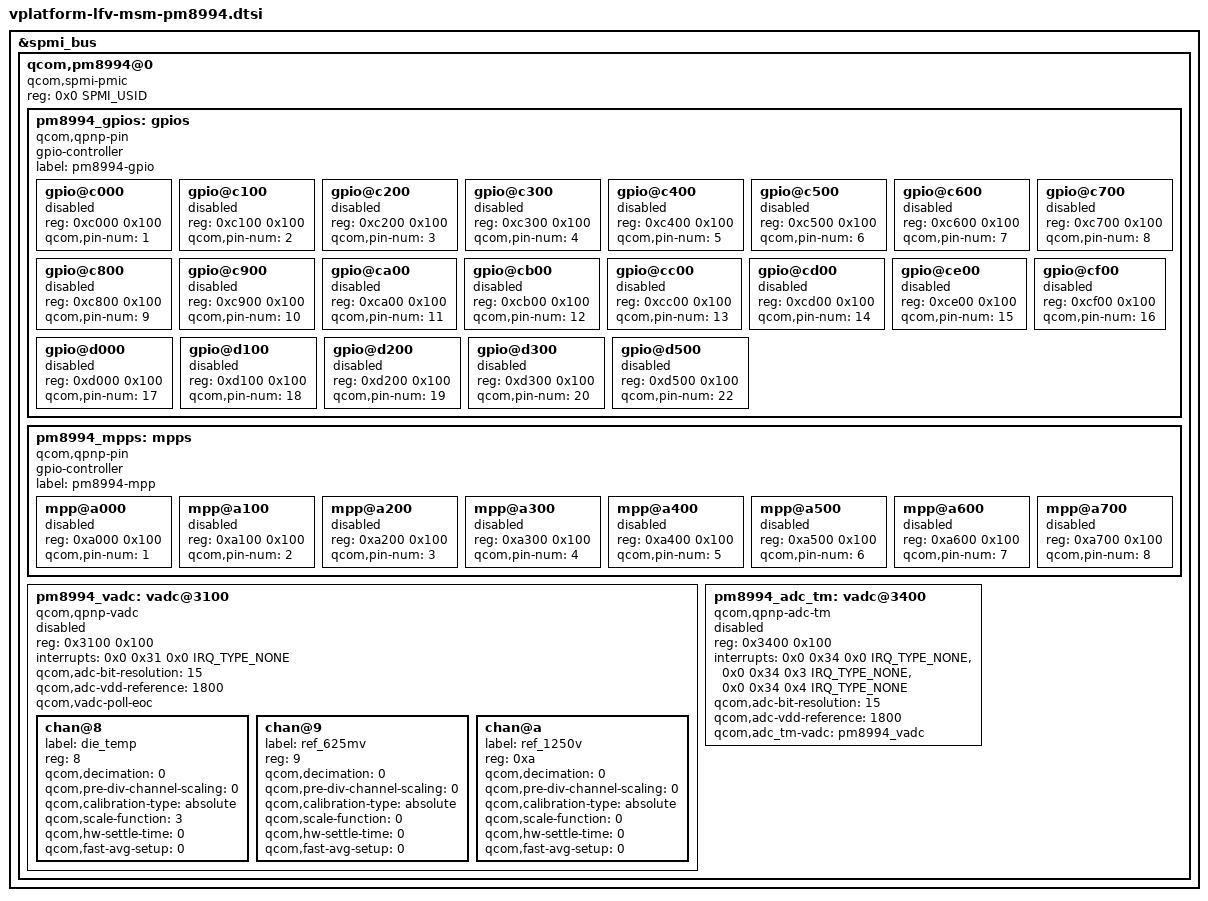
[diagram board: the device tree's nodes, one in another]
/* Copyright (c) 2018, The Linux Foundation. All rights reserved.
 *
 * This program is free software; you can redistribute it and/or modify
 * it under the terms of the GNU General Public License version 2 and
 * only version 2 as published by the Free Software Foundation.
 *
 * This program is distributed in the hope that it will be useful,
 * but WITHOUT ANY WARRANTY; without even the implied warranty of
 * MERCHANTABILITY or FITNESS FOR A PARTICULAR PURPOSE.  See the
 * GNU General Public License for more details.
 */

#include <dt-bindings/spmi/spmi.h>
#include <dt-bindings/interrupt-controller/irq.h>

&spmi_bus {
	qcom,pm8994@0 {
		compatible ="qcom,spmi-pmic";
		reg = <0x0 SPMI_USID>;
		#address-cells = <2>;
		#size-cells = <0>;

		pm8994_gpios: gpios {
			compatible = "qcom,qpnp-pin";
			gpio-controller;
			#gpio-cells = <2>;
			#address-cells = <1>;
			#size-cells = <1>;
			label = "pm8994-gpio";

			gpio@c000 {
				reg = <0xc000 0x100>;
				qcom,pin-num = <1>;
				status = "disabled";
			};

			gpio@c100 {
				reg = <0xc100 0x100>;
				qcom,pin-num = <2>;
				status = "disabled";
			};

			gpio@c200 {
				reg = <0xc200 0x100>;
				qcom,pin-num = <3>;
				status = "disabled";
			};

			gpio@c300 {
				reg = <0xc300 0x100>;
				qcom,pin-num = <4>;
				status = "disabled";
			};

			gpio@c400 {
				reg = <0xc400 0x100>;
				qcom,pin-num = <5>;
				status = "disabled";
			};

			gpio@c500 {
				reg = <0xc500 0x100>;
				qcom,pin-num = <6>;
				status = "disabled";
			};

			gpio@c600 {
				reg = <0xc600 0x100>;
				qcom,pin-num = <7>;
				status = "disabled";
			};

			gpio@c700 {
				reg = <0xc700 0x100>;
				qcom,pin-num = <8>;
				status = "disabled";
			};

			gpio@c800 {
				reg = <0xc800 0x100>;
				qcom,pin-num = <9>;
				status = "disabled";
			};

			gpio@c900 {
				reg = <0xc900 0x100>;
				qcom,pin-num = <10>;
				status = "disabled";
			};

			gpio@ca00 {
				reg = <0xca00 0x100>;
				qcom,pin-num = <11>;
				status = "disabled";
			};

			gpio@cb00 {
				reg = <0xcb00 0x100>;
				qcom,pin-num = <12>;
				status = "disabled";
			};

			gpio@cc00 {
				reg = <0xcc00 0x100>;
				qcom,pin-num = <13>;
				status = "disabled";
			};

			gpio@cd00 {
				reg = <0xcd00 0x100>;
				qcom,pin-num = <14>;
				status = "disabled";
			};

			gpio@ce00 {
				reg = <0xce00 0x100>;
				qcom,pin-num = <15>;
				status = "disabled";
			};

			gpio@cf00 {
				reg = <0xcf00 0x100>;
				qcom,pin-num = <16>;
				status = "disabled";
			};

			gpio@d000 {
				reg = <0xd000 0x100>;
				qcom,pin-num = <17>;
				status = "disabled";
			};

			gpio@d100 {
				reg = <0xd100 0x100>;
				qcom,pin-num = <18>;
				status = "disabled";
			};

			gpio@d200 {
				reg = <0xd200 0x100>;
				qcom,pin-num = <19>;
				status = "disabled";
			};

			gpio@d300 {
				reg = <0xd300 0x100>;
				qcom,pin-num = <20>;
				status = "disabled";
			};

			gpio@d500 {
				reg = <0xd500 0x100>;
				qcom,pin-num = <22>;
				status = "disabled";
			};
		};

		pm8994_mpps: mpps {
			compatible = "qcom,qpnp-pin";
			gpio-controller;
			#gpio-cells = <2>;
			#address-cells = <1>;
			#size-cells = <1>;
			label = "pm8994-mpp";

			mpp@a000 {
				reg = <0xa000 0x100>;
				qcom,pin-num = <1>;
				status = "disabled";
			};

			mpp@a100 {
				reg = <0xa100 0x100>;
				qcom,pin-num = <2>;
				status = "disabled";
			};

			mpp@a200 {
				reg = <0xa200 0x100>;
				qcom,pin-num = <3>;
				status = "disabled";
			};

			mpp@a300 {
				reg = <0xa300 0x100>;
				qcom,pin-num = <4>;
				status = "disabled";
			};

			mpp@a400 {
				reg = <0xa400 0x100>;
				qcom,pin-num = <5>;
				status = "disabled";
			};

			mpp@a500 {
				reg = <0xa500 0x100>;
				qcom,pin-num = <6>;
				status = "disabled";
			};

			mpp@a600 {
				reg = <0xa600 0x100>;
				qcom,pin-num = <7>;
				status = "disabled";
			};

			mpp@a700 {
				reg = <0xa700 0x100>;
				qcom,pin-num = <8>;
				status = "disabled";
			};
		};

		pm8994_vadc: vadc@3100 {
			compatible = "qcom,qpnp-vadc";
			reg = <0x3100 0x100>;
			#address-cells = <1>;
			#size-cells = <0>;
			interrupts = <0x0 0x31 0x0 IRQ_TYPE_NONE>;
			interrupt-names = "eoc-int-en-set";
			qcom,adc-bit-resolution = <15>;
			qcom,adc-vdd-reference = <1800>;
			qcom,vadc-poll-eoc;
			status = "disabled";

			chan@8 {
				label = "die_temp";
				reg = <8>;
				qcom,decimation = <0>;
				qcom,pre-div-channel-scaling = <0>;
				qcom,calibration-type = "absolute";
				qcom,scale-function = <3>;
				qcom,hw-settle-time = <0>;
				qcom,fast-avg-setup = <0>;
			};

			chan@9 {
				label = "ref_625mv";
				reg = <9>;
				qcom,decimation = <0>;
				qcom,pre-div-channel-scaling = <0>;
				qcom,calibration-type = "absolute";
				qcom,scale-function = <0>;
				qcom,hw-settle-time = <0>;
				qcom,fast-avg-setup = <0>;
			};

			chan@a {
				label = "ref_1250v";
				reg = <0xa>;
				qcom,decimation = <0>;
				qcom,pre-div-channel-scaling = <0>;
				qcom,calibration-type = "absolute";
				qcom,scale-function = <0>;
				qcom,hw-settle-time = <0>;
				qcom,fast-avg-setup = <0>;
			};
		};

		pm8994_adc_tm: vadc@3400 {
			compatible = "qcom,qpnp-adc-tm";
			reg = <0x3400 0x100>;
			#address-cells = <1>;
			#size-cells = <0>;
			interrupts =	<0x0 0x34 0x0 IRQ_TYPE_NONE>,
					<0x0 0x34 0x3 IRQ_TYPE_NONE>,
				     <0x0 0x34 0x4 IRQ_TYPE_NONE>;
			interrupt-names =	"eoc-int-en-set",
						"high-thr-en-set",
						"low-thr-en-set";
			qcom,adc-bit-resolution = <15>;
			qcom,adc-vdd-reference = <1800>;
			qcom,adc_tm-vadc = <&pm8994_vadc>;
			status = "disabled";
		};
	};
};
